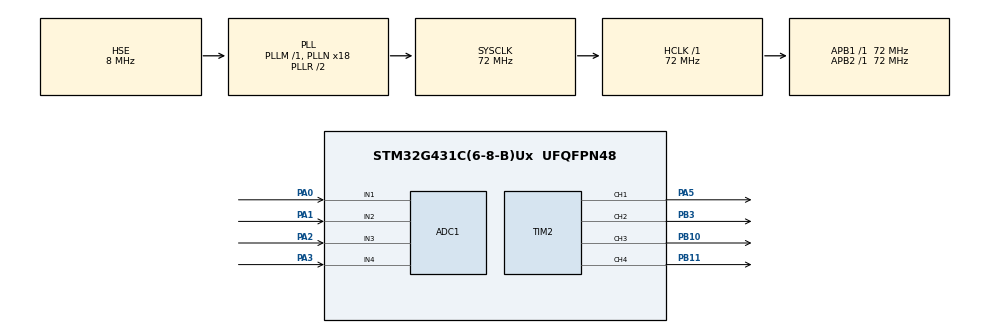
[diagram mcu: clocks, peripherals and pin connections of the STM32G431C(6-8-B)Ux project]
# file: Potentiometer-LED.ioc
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ADC1.Channel-0\#ChannelRegularConversion=ADC_CHANNEL_1
ADC1.Channel-1\#ChannelRegularConversion=ADC_CHANNEL_2
ADC1.Channel-2\#ChannelRegularConversion=ADC_CHANNEL_3
ADC1.Channel-3\#ChannelRegularConversion=ADC_CHANNEL_4
ADC1.ContinuousConvMode=ENABLE
ADC1.DMAContinuousRequests=ENABLE
ADC1.EOCSelection=ADC_EOC_SINGLE_CONV
ADC1.NbrOfConversion=4
ADC1.NbrOfConversionFlag=1
ADC1.OffsetNumber-0\#ChannelRegularConversion=ADC_OFFSET_NONE
ADC1.OffsetNumber-1\#ChannelRegularConversion=ADC_OFFSET_NONE
ADC1.OffsetNumber-2\#ChannelRegularConversion=ADC_OFFSET_NONE
ADC1.OffsetNumber-3\#ChannelRegularConversion=ADC_OFFSET_NONE
ADC1.Overrun=ADC_OVR_DATA_OVERWRITTEN
ADC1.Rank-0\#ChannelRegularConversion=1
ADC1.Rank-1\#ChannelRegularConversion=2
ADC1.Rank-2\#ChannelRegularConversion=3
ADC1.Rank-3\#ChannelRegularConversion=4
ADC1.SamplingTime-0\#ChannelRegularConversion=ADC_SAMPLETIME_2CYCLES_5
ADC1.SamplingTime-1\#ChannelRegularConversion=ADC_SAMPLETIME_2CYCLES_5
ADC1.SamplingTime-2\#ChannelRegularConversion=ADC_SAMPLETIME_2CYCLES_5
ADC1.SamplingTime-3\#ChannelRegularConversion=ADC_SAMPLETIME_2CYCLES_5
ADC1.master=1
Dma.ADC1.0.Direction=DMA_PERIPH_TO_MEMORY
Dma.ADC1.0.EventEnable=DISABLE
Dma.ADC1.0.Instance=DMA1_Channel1
Dma.ADC1.0.MemDataAlignment=DMA_MDATAALIGN_WORD
Dma.ADC1.0.MemInc=DMA_MINC_ENABLE
Dma.ADC1.0.Mode=DMA_CIRCULAR
Dma.ADC1.0.PeriphDataAlignment=DMA_PDATAALIGN_WORD
Dma.ADC1.0.PeriphInc=DMA_PINC_DISABLE
Dma.ADC1.0.Polarity=HAL_DMAMUX_REQ_GEN_RISING
Dma.ADC1.0.Priority=DMA_PRIORITY_LOW
Dma.ADC1.0.RequestNumber=1
Dma.ADC1.0.SignalID=NONE
Dma.ADC1.0.SyncEnable=DISABLE
Dma.ADC1.0.SyncPolarity=HAL_DMAMUX_SYNC_NO_EVENT
Dma.ADC1.0.SyncRequestNumber=1
Dma.ADC1.0.SyncSignalID=NONE
Dma.Request0=ADC1
Mcu.Family=STM32G4
Mcu.Name=STM32G431C(6-8-B)Ux
Mcu.Package=UFQFPN48
NVIC.DMA1_Channel1_IRQn=true\:0\:0\:false\:false\:true\:false\:true\:true
NVIC.PriorityGroup=NVIC_PRIORITYGROUP_4
PA0.Mode=IN1-Single-Ended
PA0.Signal=ADC1_IN1
PA1.Mode=IN2-Single-Ended
PA1.Signal=ADC1_IN2
PA13.Mode=Serial_Wire
PA13.Signal=SYS_JTMS-SWDIO
PA14.Mode=Serial_Wire
PA14.Signal=SYS_JTCK-SWCLK
PA2.Mode=IN3-Single-Ended
PA2.Signal=ADC1_IN3
PA3.Mode=IN4-Single-Ended
PA3.Signal=ADC1_IN4
PA5.Signal=S_TIM2_CH1
PB10.Signal=S_TIM2_CH3
PB11.Signal=S_TIM2_CH4
PB3.Signal=S_TIM2_CH2
PF0-OSC_IN.Mode=HSE-External-Oscillator
PF0-OSC_IN.Signal=RCC_OSC_IN
PF1-OSC_OUT.Mode=HSE-External-Oscillator
PF1-OSC_OUT.Signal=RCC_OSC_OUT
ProjectManager.HeapSize=0x200
ProjectManager.StackSize=0x400
ProjectManager.TargetToolchain=CMake
RCC.ADC12Freq_Value=72000000
RCC.AHBFreq_Value=72000000
RCC.APB1Freq_Value=72000000
RCC.APB1TimFreq_Value=72000000
RCC.APB2Freq_Value=72000000
RCC.APB2TimFreq_Value=72000000
RCC.CortexFreq_Value=72000000
RCC.EXTERNAL_CLOCK_VALUE=12288000
RCC.HCLKFreq_Value=72000000
RCC.HSE_VALUE=8000000
RCC.HSI48_VALUE=48000000
RCC.HSI_VALUE=16000000
RCC.LSE_VALUE=32768
RCC.PLLN=18
RCC.PLLSourceVirtual=RCC_PLLSOURCE_HSE
RCC.SYSCLKFreq_VALUE=72000000
RCC.SYSCLKSource=RCC_SYSCLKSOURCE_PLLCLK
RCC.USBFreq_Value=72000000
RCC.VCOOutputFreq_Value=144000000
SH.S_TIM2_CH1.0=TIM2_CH1,PWM Generation1 CH1
SH.S_TIM2_CH2.0=TIM2_CH2,PWM Generation2 CH2
SH.S_TIM2_CH3.0=TIM2_CH3,PWM Generation3 CH3
SH.S_TIM2_CH4.0=TIM2_CH4,PWM Generation4 CH4
TIM2.AutoReloadPreload=TIM_AUTORELOAD_PRELOAD_ENABLE
TIM2.Channel-PWM\ Generation1\ CH1=TIM_CHANNEL_1
TIM2.Channel-PWM\ Generation2\ CH2=TIM_CHANNEL_2
TIM2.Channel-PWM\ Generation3\ CH3=TIM_CHANNEL_3
TIM2.Channel-PWM\ Generation4\ CH4=TIM_CHANNEL_4
VP_SYS_VS_DBSignals.Mode=DisableDeadBatterySignals
VP_TIM2_VS_ClockSourceINT.Mode=Internal
board=custom

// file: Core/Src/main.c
/* USER CODE BEGIN Header */
/**
  ******************************************************************************
  * @file           : main.c
  * @brief          : Main program body
  ******************************************************************************
  * @attention
  *
  * Copyright (c) 2026 STMicroelectronics.
  * All rights reserved.
  *
  * This software is licensed under terms that can be found in the LICENSE file
  * in the root directory of this software component.
  * If no LICENSE file comes with this software, it is provided AS-IS.
  *
  ******************************************************************************
  */
/* USER CODE END Header */
#include "main.h"

uint32_t AD_RES_BUFFER[4];
ADC_HandleTypeDef hadc1;
DMA_HandleTypeDef hdma_adc1;

TIM_HandleTypeDef htim2;

/* USER CODE BEGIN PV */
volatile uint32_t ADC_TEST_INTEGER_0;
volatile uint32_t ADC_TEST_INTEGER_1;
volatile uint32_t ADC_TEST_INTEGER_2;
volatile uint32_t ADC_TEST_INTEGER_3;
/* USER CODE END PV */

void SystemClock_Config(void);
static void MX_GPIO_Init(void);
static void MX_DMA_Init(void);
static void MX_ADC1_Init(void);
static void MX_TIM2_Init(void);

int main(void)
{

  /* MCU Configuration--------------------------------------------------------*/

  /* Reset of all peripherals, Initializes the Flash interface and the Systick. */
  HAL_Init();

  /* Configure the system clock */
  SystemClock_Config();

  /* Initialize all configured peripherals */
  MX_GPIO_Init();
  MX_DMA_Init();
  MX_ADC1_Init();
  MX_TIM2_Init();
  HAL_TIM_PWM_Start(&htim2, TIM_CHANNEL_1);
  HAL_TIM_PWM_Start(&htim2, TIM_CHANNEL_2);
  HAL_TIM_PWM_Start(&htim2, TIM_CHANNEL_3);
  HAL_TIM_PWM_Start(&htim2, TIM_CHANNEL_4);
  HAL_ADC_Start_DMA(&hadc1, AD_RES_BUFFER, 4);

/*
  TIM2->CCR1 = 0xFFFFFFFF;//(AD_RES_BUFFER[0]);
  TIM2->CCR2 = 0xFFFFFFFF;//(AD_RES_BUFFER[1]);
  TIM2->CCR3 = 0xFFFFFFFF;//(AD_RES_BUFFER[2]);
  TIM2->CCR4 = 0xFFFFFFFF;//(AD_RES_BUFFER[3]0);
*/

  /* Infinite loop */
  while (1)
  {
    __NOP();
  }
}

void SystemClock_Config(void)
{
  RCC_OscInitTypeDef RCC_OscInitStruct = {0};
  RCC_ClkInitTypeDef RCC_ClkInitStruct = {0};

  /** Configure the main internal regulator output voltage
  */
  HAL_PWREx_ControlVoltageScaling(PWR_REGULATOR_VOLTAGE_SCALE1);

  /** Initializes the RCC Oscillators according to the specified parameters
  * in the RCC_OscInitTypeDef structure.
  */
  RCC_OscInitStruct.OscillatorType = RCC_OSCILLATORTYPE_HSE;
  RCC_OscInitStruct.HSEState = RCC_HSE_ON;
  RCC_OscInitStruct.PLL.PLLState = RCC_PLL_ON;
  RCC_OscInitStruct.PLL.PLLSource = RCC_PLLSOURCE_HSE;
  RCC_OscInitStruct.PLL.PLLM = RCC_PLLM_DIV1;
  RCC_OscInitStruct.PLL.PLLN = 18;
  RCC_OscInitStruct.PLL.PLLP = RCC_PLLP_DIV2;
  RCC_OscInitStruct.PLL.PLLQ = RCC_PLLQ_DIV2;
  RCC_OscInitStruct.PLL.PLLR = RCC_PLLR_DIV2;
  if (HAL_RCC_OscConfig(&RCC_OscInitStruct) != HAL_OK)
  {
    Error_Handler();
  }

  /** Initializes the CPU, AHB and APB buses clocks
  */
  RCC_ClkInitStruct.ClockType = RCC_CLOCKTYPE_HCLK|RCC_CLOCKTYPE_SYSCLK
                              |RCC_CLOCKTYPE_PCLK1|RCC_CLOCKTYPE_PCLK2;
  RCC_ClkInitStruct.SYSCLKSource = RCC_SYSCLKSOURCE_PLLCLK;
  RCC_ClkInitStruct.AHBCLKDivider = RCC_SYSCLK_DIV1;
  RCC_ClkInitStruct.APB1CLKDivider = RCC_HCLK_DIV1;
  RCC_ClkInitStruct.APB2CLKDivider = RCC_HCLK_DIV1;

  if (HAL_RCC_ClockConfig(&RCC_ClkInitStruct, FLASH_LATENCY_2) != HAL_OK)
  {
    Error_Handler();
  }
}

static void MX_ADC1_Init(void)
{

  ADC_MultiModeTypeDef multimode = {0};
  ADC_ChannelConfTypeDef sConfig = {0};

  /** Common config
  */
  hadc1.Instance = ADC1;
  hadc1.Init.ClockPrescaler = ADC_CLOCK_SYNC_PCLK_DIV2;
  hadc1.Init.Resolution = ADC_RESOLUTION_12B;
  hadc1.Init.DataAlign = ADC_DATAALIGN_RIGHT;
  hadc1.Init.GainCompensation = 0;
  hadc1.Init.ScanConvMode = ADC_SCAN_ENABLE;
  hadc1.Init.EOCSelection = ADC_EOC_SINGLE_CONV;
  hadc1.Init.LowPowerAutoWait = DISABLE;
  hadc1.Init.ContinuousConvMode = ENABLE;
  hadc1.Init.NbrOfConversion = 4;
  hadc1.Init.DiscontinuousConvMode = DISABLE;
  hadc1.Init.ExternalTrigConv = ADC_SOFTWARE_START;
  hadc1.Init.ExternalTrigConvEdge = ADC_EXTERNALTRIGCONVEDGE_NONE;
  hadc1.Init.DMAContinuousRequests = ENABLE;
  hadc1.Init.Overrun = ADC_OVR_DATA_OVERWRITTEN;
  hadc1.Init.OversamplingMode = DISABLE;
  if (HAL_ADC_Init(&hadc1) != HAL_OK)
  {
    Error_Handler();
  }

  /** Configure the ADC multi-mode
  */
  multimode.Mode = ADC_MODE_INDEPENDENT;
  if (HAL_ADCEx_MultiModeConfigChannel(&hadc1, &multimode) != HAL_OK)
  {
    Error_Handler();
  }

  /** Configure Regular Channel
  */
  sConfig.Channel = ADC_CHANNEL_1;
  sConfig.Rank = ADC_REGULAR_RANK_1;
  sConfig.SamplingTime = ADC_SAMPLETIME_2CYCLES_5;
  sConfig.SingleDiff = ADC_SINGLE_ENDED;
  sConfig.OffsetNumber = ADC_OFFSET_NONE;
  sConfig.Offset = 0;
  if (HAL_ADC_ConfigChannel(&hadc1, &sConfig) != HAL_OK)
  {
    Error_Handler();
  }

  /** Configure Regular Channel
  */
  sConfig.Channel = ADC_CHANNEL_2;
  sConfig.Rank = ADC_REGULAR_RANK_2;
  if (HAL_ADC_ConfigChannel(&hadc1, &sConfig) != HAL_OK)
  {
    Error_Handler();
  }

  /** Configure Regular Channel
  */
  sConfig.Channel = ADC_CHANNEL_3;
  sConfig.Rank = ADC_REGULAR_RANK_3;
  if (HAL_ADC_ConfigChannel(&hadc1, &sConfig) != HAL_OK)
  {
    Error_Handler();
  }

  /** Configure Regular Channel
  */
  sConfig.Channel = ADC_CHANNEL_4;
  sConfig.Rank = ADC_REGULAR_RANK_4;
  if (HAL_ADC_ConfigChannel(&hadc1, &sConfig) != HAL_OK)
  {
    Error_Handler();
  }

}

void HAL_ADC_ConvCpltCallback(ADC_HandleTypeDef* hadc)
{

  TIM2->CCR1 = (AD_RES_BUFFER[0]);
  TIM2->CCR2 = (AD_RES_BUFFER[1]);
  TIM2->CCR3 = (AD_RES_BUFFER[2]);
  TIM2->CCR4 = (AD_RES_BUFFER[3]);

  ADC_TEST_INTEGER_0 = AD_RES_BUFFER[0];
  ADC_TEST_INTEGER_1 = AD_RES_BUFFER[1];
  ADC_TEST_INTEGER_2 = AD_RES_BUFFER[2];
  ADC_TEST_INTEGER_3 = AD_RES_BUFFER[3];

}

static void MX_TIM2_Init(void)
{

  TIM_ClockConfigTypeDef sClockSourceConfig = {0};
  TIM_MasterConfigTypeDef sMasterConfig = {0};
  TIM_OC_InitTypeDef sConfigOC = {0};

  htim2.Instance = TIM2;
  htim2.Init.Prescaler = 0;
  htim2.Init.CounterMode = TIM_COUNTERMODE_UP;
  htim2.Init.Period = 4096;
  htim2.Init.ClockDivision = TIM_CLOCKDIVISION_DIV1;
  htim2.Init.AutoReloadPreload = TIM_AUTORELOAD_PRELOAD_ENABLE;
  if (HAL_TIM_Base_Init(&htim2) != HAL_OK)
  {
    Error_Handler();
  }
  sClockSourceConfig.ClockSource = TIM_CLOCKSOURCE_INTERNAL;
  if (HAL_TIM_ConfigClockSource(&htim2, &sClockSourceConfig) != HAL_OK)
  {
    Error_Handler();
  }
  if (HAL_TIM_PWM_Init(&htim2) != HAL_OK)
  {
    Error_Handler();
  }
  sMasterConfig.MasterOutputTrigger = TIM_TRGO_RESET;
  sMasterConfig.MasterSlaveMode = TIM_MASTERSLAVEMODE_DISABLE;
  if (HAL_TIMEx_MasterConfigSynchronization(&htim2, &sMasterConfig) != HAL_OK)
  {
    Error_Handler();
  }
  sConfigOC.OCMode = TIM_OCMODE_PWM1;
  sConfigOC.Pulse = 0;
  sConfigOC.OCPolarity = TIM_OCPOLARITY_HIGH;
  sConfigOC.OCFastMode = TIM_OCFAST_DISABLE;
  if (HAL_TIM_PWM_ConfigChannel(&htim2, &sConfigOC, TIM_CHANNEL_1) != HAL_OK)
  {
    Error_Handler();
  }
  if (HAL_TIM_PWM_ConfigChannel(&htim2, &sConfigOC, TIM_CHANNEL_2) != HAL_OK)
  {
    Error_Handler();
  }
  if (HAL_TIM_PWM_ConfigChannel(&htim2, &sConfigOC, TIM_CHANNEL_3) != HAL_OK)
  {
    Error_Handler();
  }
  if (HAL_TIM_PWM_ConfigChannel(&htim2, &sConfigOC, TIM_CHANNEL_4) != HAL_OK)
  {
    Error_Handler();
  }
  HAL_TIM_MspPostInit(&htim2);

}

static void MX_DMA_Init(void)
{

  /* DMA controller clock enable */
  __HAL_RCC_DMAMUX1_CLK_ENABLE();
  __HAL_RCC_DMA1_CLK_ENABLE();

  /* DMA interrupt init */
  /* DMA1_Channel1_IRQn interrupt configuration */
  HAL_NVIC_SetPriority(DMA1_Channel1_IRQn, 0, 0);
  HAL_NVIC_EnableIRQ(DMA1_Channel1_IRQn);

}

static void MX_GPIO_Init(void)
{

  /* GPIO Ports Clock Enable */
  __HAL_RCC_GPIOF_CLK_ENABLE();
  __HAL_RCC_GPIOA_CLK_ENABLE();
  __HAL_RCC_GPIOB_CLK_ENABLE();

}

void Error_Handler(void)
{
  __disable_irq();
  while (1)
  {
  }
}
